# STM32L412TBY6P register map
File version: 1.0
Registers are 32-bit, access not given, reset 0x0 unless marked. A register's access mark holds for its fields unless they carry their own. Offsets are from the block's base; [hi:lo] are bit positions; {n}, {i} and the like mark numbered series.

## WWDG
Base 0x40002C00
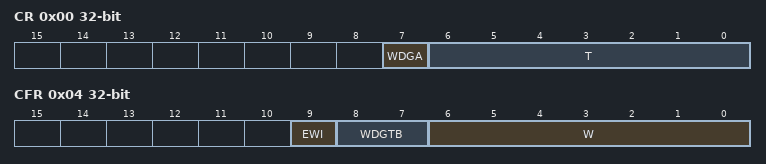
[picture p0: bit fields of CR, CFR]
0x00 CR
  [7] WDGA, [6:0] T
0x04 CFR
  [9] EWI, [8:7] WDGTB, [6:0] W
0x08 SR
  [0] EWIF

## IWDG
Base 0x40003000
0x00 KR
  [15:0] KEY
0x04 PR
  [2:0] PR
0x08 RLR
  [11:0] RL
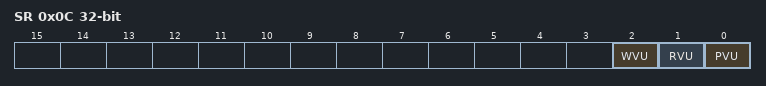
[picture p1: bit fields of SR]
0x0C SR
  [2] WVU, [1] RVU, [0] PVU
0x10 WINR
  [11:0] WIN

## TAMP
Base 0x40003400
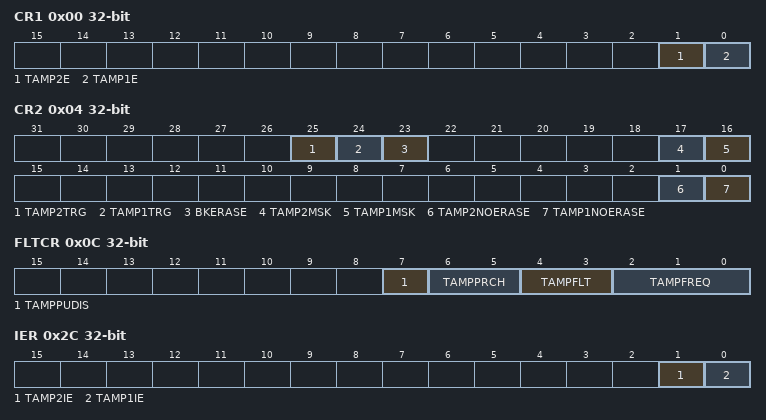
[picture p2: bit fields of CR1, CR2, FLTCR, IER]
0x00 CR1
  [1] TAMP2E, [0] TAMP1E
0x04 CR2
  [25] TAMP2TRG, [24] TAMP1TRG, [23] BKERASE, [17] TAMP2MSK, [16] TAMP1MSK, [1] TAMP2NOERASE, [0] TAMP1NOERASE
0x0C FLTCR
  [7] TAMPPUDIS, [6:5] TAMPPRCH, [4:3] TAMPFLT, [2:0] TAMPFREQ
0x2C IER
  [1] TAMP2IE, [0] TAMP1IE
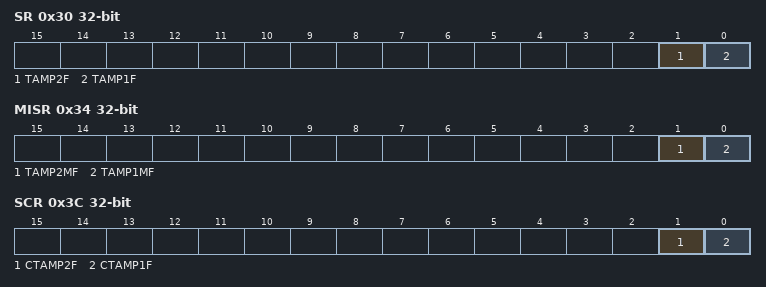
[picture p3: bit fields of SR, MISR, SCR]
0x30 SR
  [1] TAMP2F, [0] TAMP1F
0x34 MISR
  [1] TAMP2MF, [0] TAMP1MF
0x3C SCR
  [1] CTAMP2F, [0] CTAMP1F
{0x100+4i} BKP{i}R (i=0..31)

## SPI2
Base 0x40003800
Same registers: SPI1 0x40013000
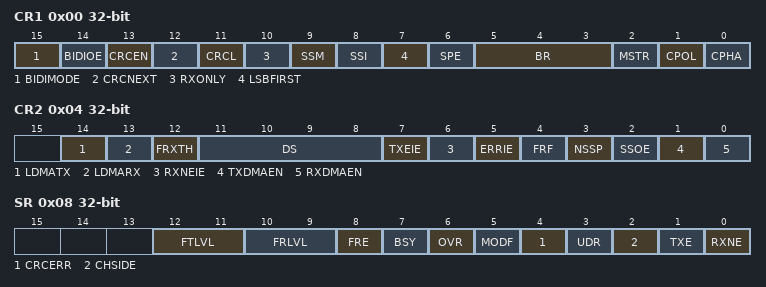
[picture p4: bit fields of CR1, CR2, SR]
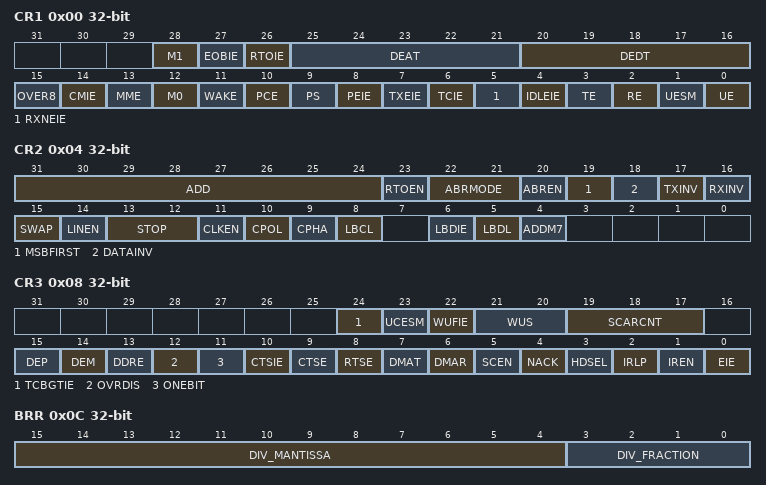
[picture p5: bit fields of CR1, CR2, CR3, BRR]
0x00 CR1
  [15] BIDIMODE, [14] BIDIOE, [13] CRCEN, [12] CRCNEXT, [11] CRCL, [10] RXONLY, [9] SSM, [8] SSI, [7] LSBFIRST, [6] SPE, [5:3] BR, [2] MSTR, [1] CPOL, [0] CPHA
0x04 CR2
  [14] LDMATX, [13] LDMARX, [12] FRXTH, [11:8] DS, [7] TXEIE, [6] RXNEIE, [5] ERRIE, [4] FRF, [3] NSSP, [2] SSOE, [1] TXDMAEN, [0] RXDMAEN
0x08 SR
  [12:11] FTLVL, [10:9] FRLVL, [8] FRE, [7] BSY, [6] OVR, [5] MODF, [4] CRCERR, [3] UDR, [2] CHSIDE, [1] TXE, [0] RXNE
0x0C DR
  [15:0] DR
0x10 CRCPR
  [15:0] CRCPOLY
0x14 RXCRCR
  [15:0] RXCRC
0x18 TXCRCR
  [15:0] TXCRC

## USART2
Base 0x40004400
Same registers: USART3 0x40004800, LPUART1 0x40008000, USART1 0x40013800
0x00 CR1
  [28] M1, [27] EOBIE, [26] RTOIE, [25:21] DEAT, [20:16] DEDT, [15] OVER8, [14] CMIE, [13] MME, [12] M0, [11] WAKE, [10] PCE, [9] PS, [8] PEIE, [7] TXEIE, [6] TCIE, [5] RXNEIE, [4] IDLEIE, [3] TE, [2] RE, [1] UESM, [0] UE
0x04 CR2
  [31:24] ADD, [23] RTOEN, [22:21] ABRMODE, [20] ABREN, [19] MSBFIRST, [18] DATAINV, [17] TXINV, [16] RXINV, [15] SWAP, [14] LINEN, [13:12] STOP, [11] CLKEN, [10] CPOL, [9] CPHA, [8] LBCL, [6] LBDIE, [5] LBDL, [4] ADDM7
0x08 CR3
  [24] TCBGTIE, [23] UCESM, [22] WUFIE, [21:20] WUS, [19:17] SCARCNT, [15] DEP, [14] DEM, [13] DDRE, [12] OVRDIS, [11] ONEBIT, [10] CTSIE, [9] CTSE, [8] RTSE, [7] DMAT, [6] DMAR, [5] SCEN, [4] NACK, [3] HDSEL, [2] IRLP, [1] IREN, [0] EIE
0x0C BRR
  [15:4] DIV_MANTISSA, [3:0] DIV_FRACTION
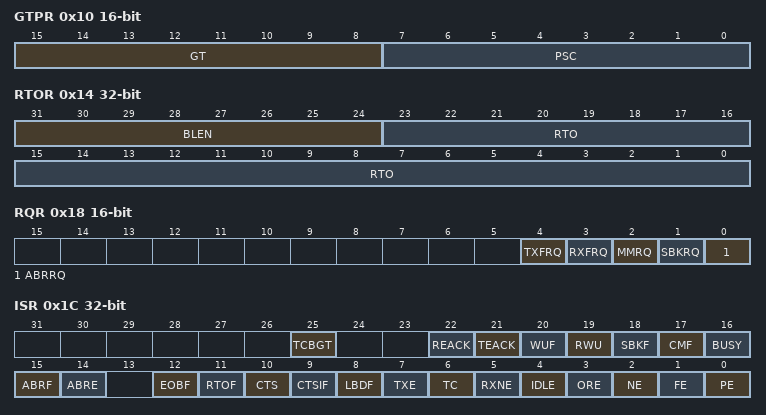
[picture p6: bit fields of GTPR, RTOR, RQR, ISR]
0x10 GTPR 16-bit
  [15:8] GT, [7:0] PSC
0x14 RTOR
  [31:24] BLEN, [23:0] RTO
0x18 RQR 16-bit
  [4] TXFRQ, [3] RXFRQ, [2] MMRQ, [1] SBKRQ, [0] ABRRQ
0x1C ISR
  [25] TCBGT, [22] REACK, [21] TEACK, [20] WUF, [19] RWU, [18] SBKF, [17] CMF, [16] BUSY, [15] ABRF, [14] ABRE, [12] EOBF, [11] RTOF, [10] CTS, [9] CTSIF, [8] LBDF, [7] TXE, [6] TC, [5] RXNE, [4] IDLE, [3] ORE, [2] NE, [1] FE, [0] PE
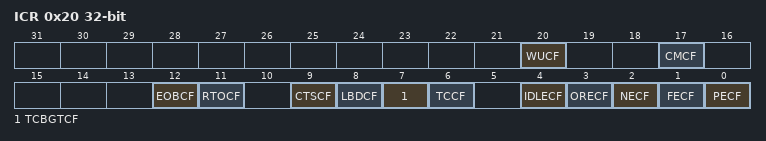
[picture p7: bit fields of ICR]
0x20 ICR
  [20] WUCF, [17] CMCF, [12] EOBCF, [11] RTOCF, [9] CTSCF, [8] LBDCF, [7] TCBGTCF, [6] TCCF, [4] IDLECF, [3] ORECF, [2] NECF, [1] FECF, [0] PECF
0x24 RDR 16-bit
  [8:0] RDR
0x28 TDR 16-bit
  [8:0] TDR

## I2C1
Base 0x40005400
Same registers: I2C2 0x40005800, I2C3 0x40005C00
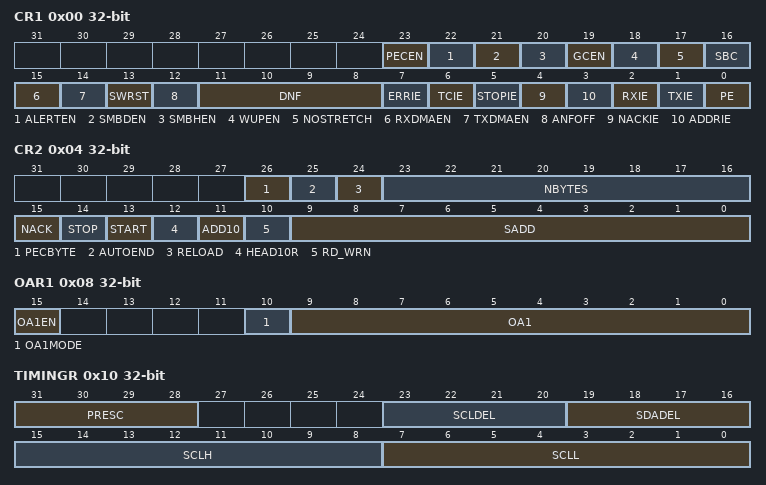
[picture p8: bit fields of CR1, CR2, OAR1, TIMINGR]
0x00 CR1
  [23] PECEN, [22] ALERTEN, [21] SMBDEN, [20] SMBHEN, [19] GCEN, [18] WUPEN, [17] NOSTRETCH, [16] SBC, [15] RXDMAEN, [14] TXDMAEN, [13] SWRST, [12] ANFOFF, [11:8] DNF, [7] ERRIE, [6] TCIE, [5] STOPIE, [4] NACKIE, [3] ADDRIE, [2] RXIE, [1] TXIE, [0] PE
0x04 CR2
  [26] PECBYTE, [25] AUTOEND, [24] RELOAD, [23:16] NBYTES, [15] NACK, [14] STOP, [13] START, [12] HEAD10R, [11] ADD10, [10] RD_WRN, [9:0] SADD
0x08 OAR1
  [15] OA1EN, [10] OA1MODE, [9:0] OA1
0x0C OAR2
  [15] OA2EN, [10] OA2MASK04, [10:9] OA2MASK06, [10:8] OA2MSK, [7:1] OA2
0x10 TIMINGR
  [31:28] PRESC, [23:20] SCLDEL, [19:16] SDADEL, [15:8] SCLH, [7:0] SCLL
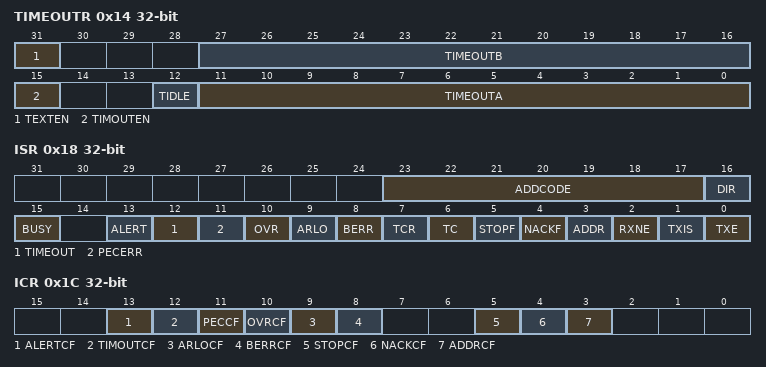
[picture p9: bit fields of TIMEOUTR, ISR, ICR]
0x14 TIMEOUTR
  [31] TEXTEN, [27:16] TIMEOUTB, [15] TIMOUTEN, [12] TIDLE, [11:0] TIMEOUTA
0x18 ISR
  [23:17] ADDCODE, [16] DIR, [15] BUSY, [13] ALERT, [12] TIMEOUT, [11] PECERR, [10] OVR, [9] ARLO, [8] BERR, [7] TCR, [6] TC, [5] STOPF, [4] NACKF, [3] ADDR, [2] RXNE, [1] TXIS, [0] TXE
0x1C ICR
  [13] ALERTCF, [12] TIMOUTCF, [11] PECCF, [10] OVRCF, [9] ARLOCF, [8] BERRCF, [5] STOPCF, [4] NACKCF, [3] ADDRCF
0x20 PECR
  [7:0] PEC
0x24 RXDR
  [7:0] RXDATA
0x28 TXDR
  [7:0] TXDATA
